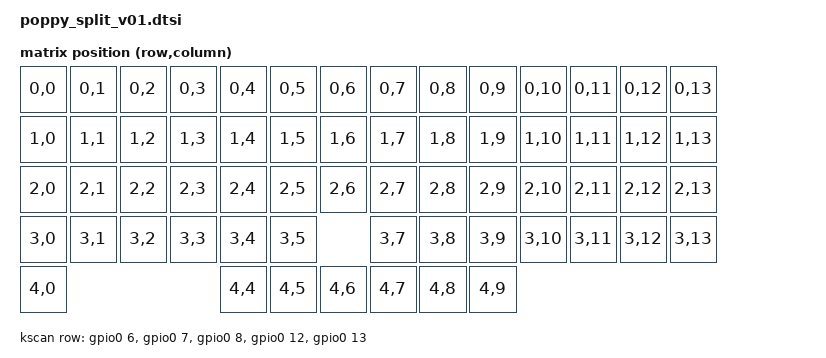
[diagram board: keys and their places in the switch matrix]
// This file was generated from a template. Edit it to match your keyboard.
// See https://zmk.dev/docs/development/hardware-integration/new-shield for more
// instructions.

#include <dt-bindings/zmk/matrix_transform.h>

#include "poppy_split_v01-layouts.dtsi"

// The wired split UART is board-specific; see boards/<board>.overlay.

/ {
    chosen {
        zmk,physical-layout = &default_layout;
    };

    kscan: kscan {
        // If the hardware does not use a switch matrix, change this to the
        // appropriate driver and update the properties below to match.
        // See https://zmk.dev/docs/config/kscan for supported key scan drivers.
        compatible = "zmk,kscan-gpio-matrix";
        // Set this to "col2row" or "row2col" to match the hardware. If using
        // "row2col", change the col-gpios in the _left.overlay and _right.overlay
        // files to (GPIO_ACTIVE_HIGH | GPIO_PULL_DOWN) and the row-gpios here to
        // GPIO_ACTIVE_HIGH.
        diode-direction = "col2row";
        wakeup-source;

        // Pins use RP2040 GP numbers (&gpio0 N), which match the controller's
        // silkscreen. &pro_micro N would mean Arduino D-numbers instead.
        // Same row pins on both halves.
        row-gpios
            = <&gpio0  6 (GPIO_ACTIVE_HIGH | GPIO_PULL_DOWN)>  // row 0: GP6,  left edge
            , <&gpio0  7 (GPIO_ACTIVE_HIGH | GPIO_PULL_DOWN)>  // row 1: GP7,  left edge
            , <&gpio0  8 (GPIO_ACTIVE_HIGH | GPIO_PULL_DOWN)>  // row 2: GP8,  left edge
            , <&gpio0 12 (GPIO_ACTIVE_HIGH | GPIO_PULL_DOWN)>  // row 3: GP12, bottom edge
            , <&gpio0 13 (GPIO_ACTIVE_HIGH | GPIO_PULL_DOWN)>  // row 4: GP13, bottom edge
            ;
    };

    default_transform: default_transform {
        // See https://zmk.dev/docs/development/hardware-integration/new-shield#matrix-transform
        // for how to configure this
        compatible = "zmk,matrix-transform";
        columns = <14>;
        rows = <5>;

        map = <
            RC(0, 0) RC(0, 1) RC(0, 2) RC(0, 3) RC(0, 4) RC(0, 5) RC(0, 6)    RC(0, 7) RC(0, 8) RC(0, 9) RC(0, 10) RC(0, 11) RC(0, 12) RC(0, 13)
            RC(1, 0) RC(1, 1) RC(1, 2) RC(1, 3) RC(1, 4) RC(1, 5) RC(1, 6)    RC(1, 7) RC(1, 8) RC(1, 9) RC(1, 10) RC(1, 11) RC(1, 12) RC(1, 13)
            RC(2, 0) RC(2, 1) RC(2, 2) RC(2, 3) RC(2, 4) RC(2, 5) RC(2, 6)    RC(2, 7) RC(2, 8) RC(2, 9) RC(2, 10) RC(2, 11) RC(2, 12) RC(2, 13)
            RC(3, 0) RC(3, 1) RC(3, 2) RC(3, 3) RC(3, 4) RC(3, 5)             RC(3, 7) RC(3, 8) RC(3, 9) RC(3, 10) RC(3, 11) RC(3, 12) RC(3, 13)
            RC(4, 0)                            RC(4, 4) RC(4, 5) RC(4, 6)    RC(4, 7) RC(4, 8) RC(4, 9)
        >;
    };
};
